# STM32U545 register map
File version: 1.0
CPU: CM33 r0p1, little endian, MPU, FPU, 4 interrupt priority bits
Registers are 32-bit, read-write, reset 0x0 unless marked. A register's access mark holds for its fields unless they carry their own. Offsets are from the block's base; [hi:lo] are bit positions; {n}, {i} and the like mark numbered series.

## HASH — Hash processor
Base 0x420C0400
Same registers: SEC_HASH 0x520C0400
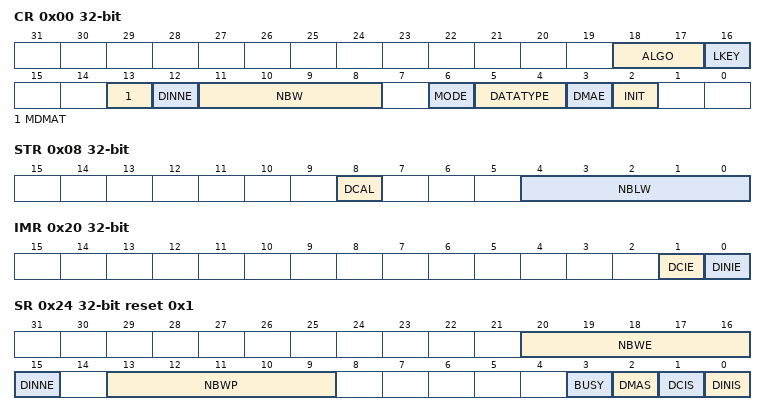
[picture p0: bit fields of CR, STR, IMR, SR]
0x00 CR access per field — control register
  [18:17] ALGO rw — Algorithm selection
  [16] LKEY rw — Long key selection
  [13] MDMAT rw — Multiple DMA Transfers
  [12] DINNE ro — DIN not empty
  [11:8] NBW ro — Number of words already pushed
  [6] MODE rw — Mode selection
  [5:4] DATATYPE rw — Data type selection
  [3] DMAE rw — DMA enable
  [2] INIT wo — Initialize message digest calculation
0x04 DIN wo — data input register
  [31:0] DATAIN — Data input
0x08 STR access per field — start register
  [8] DCAL wo — Digest calculation
  [4:0] NBLW rw — Number of valid bits in the last word of the message
{0xC+4i} HRA{i} ro (i=0..4) — HASH aliased digest register {i}
  [31:0] H{i}
0x20 IMR — interrupt enable register
  [1] DCIE — Digest calculation completion interrupt enable
  [0] DINIE — Data input interrupt enable
0x24 SR access per field reset 0x1 — status register
  [20:16] NBWE ro — Number of words expected
  [15] DINNE ro — DIN not empty
  [13:9] NBWP ro — Number of words already pushed
  [3] BUSY ro — Busy bit
  [2] DMAS ro — DMA Status
  [1] DCIS rw — Digest calculation completion interrupt status
  [0] DINIS rw — Data input interrupt status
{0xF8+4i} CSR{i} (i=0..53) — context swap registers
  [31:0] CS{i}
0x310 HR0 ro — digest register 0
  [31:0] H0
0x314 HR1 ro — digest register 1
  [31:0] H1
0x318 HR2 ro — digest register 4
  [31:0] H2
0x31C HR3 ro — digest register 3
  [31:0] H3
0x320 HR4 ro — digest register 4
  [31:0] H4
{0x310+4i} HR{i} ro (i=5..7) — supplementary digest register {i}
  [31:0] H{i}

## ICache
Base 0x40030400
Same registers: SEC_ICache 0x50030400
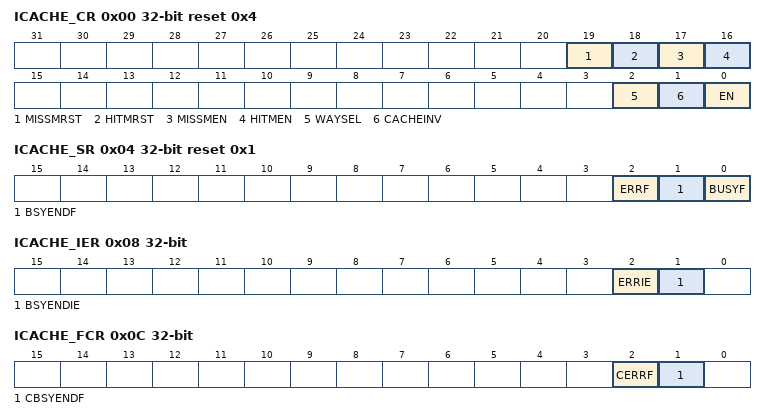
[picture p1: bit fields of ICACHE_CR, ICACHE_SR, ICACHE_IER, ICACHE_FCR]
0x00 ICACHE_CR access per field reset 0x4 — ICACHE control register
  [19] MISSMRST rw, [18] HITMRST rw, [17] MISSMEN rw, [16] HITMEN rw, [2] WAYSEL rw, [1] CACHEINV wo, [0] EN rw
0x04 ICACHE_SR ro reset 0x1 — ICACHE status register
  [2] ERRF, [1] BSYENDF, [0] BUSYF
0x08 ICACHE_IER — ICACHE interrupt enable register
  [2] ERRIE, [1] BSYENDIE
0x0C ICACHE_FCR wo — ICACHE flag clear register
  [2] CERRF, [1] CBSYENDF
0x10 ICACHE_HMONR ro — ICACHE hit monitor register
  [31:0] HITMON
0x14 ICACHE_MMONR ro — ICACHE miss monitor register
  [15:0] MISSMON
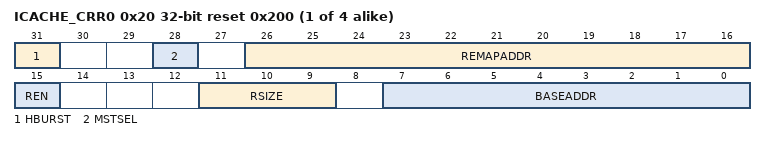
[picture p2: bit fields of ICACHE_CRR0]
{0x20+4i} ICACHE_CRR{i} reset 0x200 (i=0..3) — ICACHE region configuration register
  [31] HBURST, [28] MSTSEL, [26:16] REMAPADDR, [15] REN, [11:9] RSIZE, [7:0] BASEADDR

## IWDG — Independent watchdog
Base 0x40003000
Same registers: SEC_IWDG 0x50003000
0x00 KR wo — Key register
  [15:0] KEY — Key value (write only, read 0x0000)
0x04 PR — Prescaler register
  [3:0] PR — Prescaler divider
0x08 RLR reset 0xFFF — Reload register
  [11:0] RL — Watchdog counter reload value
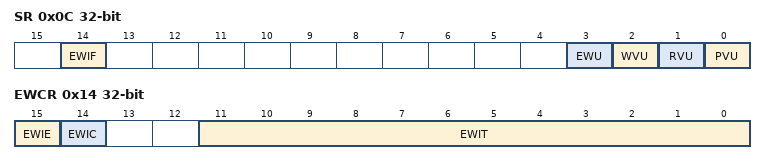
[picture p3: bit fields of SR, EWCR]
0x0C SR ro — Status register
  [14] EWIF — Watchdog Early interrupt flag
  [3] EWU — Watchdog interrupt comparator value update
  [2] WVU — Watchdog counter window value update
  [1] RVU — Watchdog counter reload value update
  [0] PVU — Watchdog prescaler value update
0x10 WINR reset 0xFFF — Window register
  [11:0] WIN — Watchdog counter window value
0x14 EWCR — IWDG early wakeup interrupt register
  [15] EWIE — Watchdog early interrupt enable
  [14] EWIC — Watchdog early interrupt acknowledge
  [11:0] EWIT — Watchdog counter window value

## LPGPIO1
Base 0x46020000
Same registers: SEC_LPGPIO1 0x56020000
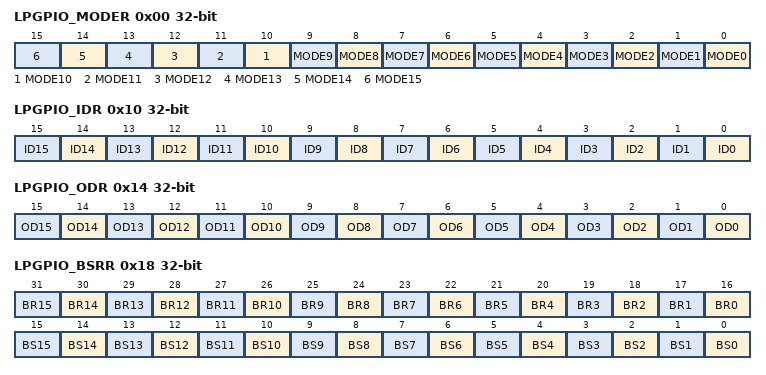
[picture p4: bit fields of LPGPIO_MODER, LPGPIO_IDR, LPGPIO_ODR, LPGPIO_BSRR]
0x00 LPGPIO_MODER — LPGPIO port mode register
  [n] MODE{n} (n=0..15)
0x10 LPGPIO_IDR ro — LPGPIO port input data register
  [n] ID{n} (n=0..15)
0x14 LPGPIO_ODR — LPGPIO port output data register
  [n] OD{n} (n=0..15)
0x18 LPGPIO_BSRR wo — LPGPIO port bit set/reset register
  [n+16] BR{n} (n=0..15), [n] BS{n} (n=0..15)
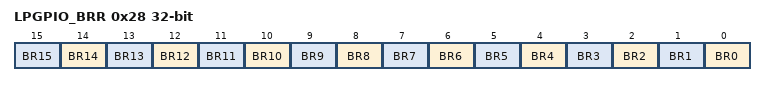
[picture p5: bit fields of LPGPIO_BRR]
0x28 LPGPIO_BRR wo — LPGPIO port bit reset register
  [n] BR{n} (n=0..15)

## Notices in the file
Copyright (c) 2023 STMicroelectronics.
SPDX-License-Identifier: Apache-2.0
Licensed under the Apache License, Version 2.0 (the "License");
you may not use this file except in compliance with the License.
You may obtain a copy of the License at
http://www.apache.org/licenses/LICENSE-2.0
Unless required by applicable law or agreed to in writing, software
distributed under the License is distributed on an "AS IS" BASIS,
WITHOUT WARRANTIES OR CONDITIONS OF ANY KIND, either express or implied.
See the License for the specific language governing permissions and
limitations under the License.
